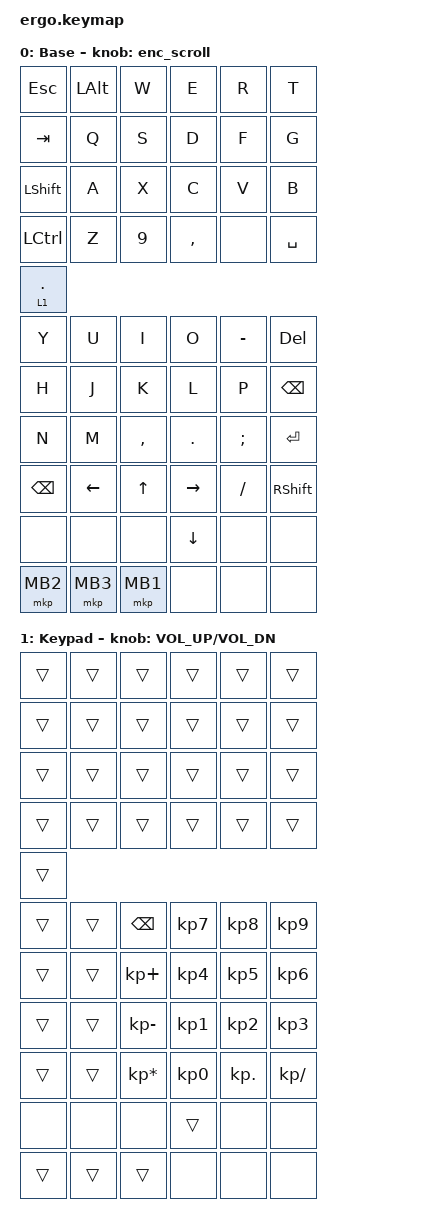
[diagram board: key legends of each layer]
#include <behaviors.dtsi>
#include <dt-bindings/zmk/keys.h>
#include <dt-bindings/zmk/bt.h>
/* Raise scroll velocity BEFORE including pointing.h. The default (10) is often
   too low for an encoder to register a wheel tick per detent - a known reason
   encoder &msc scroll appears dead. Must be defined before the header. */
#define ZMK_POINTING_DEFAULT_SCRL_VAL 80
#include <dt-bindings/zmk/pointing.h> /* &mkp for the trackpad buttons; &msc scroll */

/ {
    behaviors {
        /*
         * Positional home row mods. Studio can't tune behavior timing yet,
         * so these live here in the keymap. Usage in bindings (or in Studio):
         *     &hml LGUI A   -> hold = Left GUI, tap = A
         *     &hmr RGUI L   -> hold = Right GUI, tap = L
         *
         * "balanced" + require-prior-idle-ms keeps fast typing as taps;
         * hold-trigger-key-positions only lets a mod engage when a key on the
         * OPPOSITE hand is pressed, which kills the usual same-hand misfires.
         *   left  hand  = positions 0..24   right hand = positions 25..60
         * Tune the three *-ms values to taste once you've typed on it.
         */
        hml: home_row_mod_left {
            compatible = "zmk,behavior-hold-tap";
            #binding-cells = <2>;
            flavor = "balanced";
            tapping-term-ms = <280>;
            quick-tap-ms = <175>;
            require-prior-idle-ms = <150>;
            hold-trigger-on-release;
            bindings = <&kp>, <&kp>;
            /* opposite (right) hand */
            hold-trigger-key-positions = <25 26 27 28 29 30 31 32 33 34 35 36 37 38 39 40 41 42 43 44 45 46 47 48 49 50 51 52 53 54 55 56 57 58 59 60>;
        };
        hmr: home_row_mod_right {
            compatible = "zmk,behavior-hold-tap";
            #binding-cells = <2>;
            flavor = "balanced";
            tapping-term-ms = <280>;
            quick-tap-ms = <175>;
            require-prior-idle-ms = <150>;
            hold-trigger-on-release;
            bindings = <&kp>, <&kp>;
            /* opposite (left) hand */
            hold-trigger-key-positions = <0 1 2 3 4 5 6 7 8 9 10 11 12 13 14 15 16 17 18 19 20 21 22 23 24>;
        };

        /*
         * Encoder -> mouse scroll wheel (used by the Base layer below).
         * Wraps &msc so a turn emits scroll. Requires CONFIG_ZMK_POINTING=y.
         */
        enc_scroll: enc_scroll {
            compatible = "zmk,behavior-sensor-rotate";
            #sensor-binding-cells = <0>;
            bindings = <&msc SCRL_UP>, <&msc SCRL_DOWN>;
            tap-ms = <30>;
        };
    };

    combos {
        compatible = "zmk,combos";

        /*
         * Your board has no spare keys (all 53 switches are assigned), so
         * these actions are chords instead of dedicated keys. A combo fires
         * when its key-positions are pressed together within timeout-ms.
         * Combos are defined here in the keymap (Studio can't edit them yet).
         */

        /* ESC + Del (top outer corners) -> unlock ZMK Studio.
           Position-based, so it works regardless of the keycodes there. */
        combo_studio_unlock {
            timeout-ms = <75>;
            key-positions = <0 30>;
            bindings = <&studio_unlock>;
        };
    };

    keymap {
        compatible = "zmk,keymap";

        default_layer {
            display-name = "Base";
            /*
             * Bindings follow the combined transform in ergo.dtsi:
             * first the 25 LEFT positions, then the 36 RIGHT positions.
             */
            bindings = <
                /* ============ LEFT (positions 0..24) ============ */
                &kp ESC   &kp LALT  &kp W     &kp E     &kp R     &kp T
                &kp TAB   &kp Q     &kp S     &kp D     &kp F     &kp G
                &kp LSHFT &kp A     &kp X     &kp C     &kp V     &kp B
                &kp LCTRL &kp Z     &kp N9    &kp COMMA &none     &kp SPACE
                /* Left thumb: TAP = period, HOLD = keypad layer (layer 1).
                   This is your momentary key - hold it to type numbers. */
                &lt 1 DOT

                /* ============ RIGHT (positions 25..60) ============ */
                /* Row 0 */
                &kp Y     &kp U     &kp I     &kp O     &kp MINUS &kp DEL
                /* Row 1 */
                &kp H     &kp J     &kp K     &kp L     &kp P     &kp BSPC
                /* Row 2 */
                &kp N     &kp M     &kp COMMA &kp DOT   &kp SEMI  &kp RET
                /* Row 3 */
                &kp BSPC  &kp LEFT  &kp UP    &kp RIGHT &kp FSLH  &kp RSHFT
                /* Row 4 (positions 49-54): only DOWN (pos 52) is a real key.
                   49,50,51,53,54 are unpopulated matrix slots - no physical
                   switch exists there - so they MUST stay &none. */
                &none     &none     &none     &kp DOWN  &none     &none
                /* Row 5: the 3 keys under the trackpad = mouse buttons.
                   (Restored to plain clicks while we isolate the auto-mouse-
                   layer issue. MB1=left, MB2=right, MB3=middle.) */
                &mkp MB2  &mkp MB3  &mkp MB1  &none     &none     &none
            >;

            /* Encoder = SCROLL on base. Now uses the boosted scroll value above.
               If wheel scroll STILL doesn't register (XIAO mouse-HID can be
               flaky), swap this one line for reliable page-scroll:
                 sensor-bindings = <&inc_dec_kp PG_UP PG_DN>;
               which uses the same proven keycode path as the volume binding. */
            sensor-bindings = <&enc_scroll>;
        };

        /*
         * Keypad layer (index 1). Held via the left-thumb &lt 1 key.
         *
         * RIGHT half = numpad, transcribed from your screenshot (image 2):
         * the numbers, +, -, / and backspace read clearly. The key marked
         * (?) below I could NOT read with confidence - it's my best guess;
         * open this layer in Studio next to your saved one and fix it if
         * wrong. LEFT half is left &trans (your letters/Esc/etc. still work
         * while you hold), since image 2's left side was too blurry to trust.
         * Adjust any of this freely in Studio - it's all keymap, fully editable.
         */
        keypad_layer {
            display-name = "Keypad";
            bindings = <
                /* ============ LEFT (positions 0..24) = transparent ======== */
                &trans    &trans    &trans    &trans    &trans    &trans
                &trans    &trans    &trans    &trans    &trans    &trans
                &trans    &trans    &trans    &trans    &trans    &trans
                &trans    &trans    &trans    &trans    &trans    &trans
                &trans

                /* ============ RIGHT (positions 25..60) = numpad =========== */
                /* Row 0 */
                &trans    &trans    &kp BSPC      &kp KP_N7  &kp KP_N8  &kp KP_N9
                /* Row 1 */
                &trans    &trans    &kp KP_PLUS   &kp KP_N4  &kp KP_N5  &kp KP_N6
                /* Row 2 */
                &trans    &trans    &kp KP_MINUS  &kp KP_N1  &kp KP_N2  &kp KP_N3
                /* Row 3  (KP_MULTIPLY at pos 45 is the (?) best-guess key) */
                &trans    &trans    &kp KP_MULTIPLY &kp KP_N0 &kp KP_DOT &kp KP_DIVIDE
                /* Row 4: dead matrix slots stay &none; 52 falls through. */
                &none     &none     &none     &trans    &none     &none
                /* Row 5: trackpad buttons fall through (still click). */
                &trans    &trans    &trans    &none     &none     &none
            >;

            /* Encoder = VOLUME while the keypad layer is held (your preference). */
            sensor-bindings = <&inc_dec_kp C_VOL_UP C_VOL_DN>;
        };

        /*
         * One spare layer kept in reserve. It's invisible on a normal boot
         * (you still have just your 2 layers), but it lets you ADD a layer
         * from ZMK Studio later without reflashing. Delete this line if you
         * truly want none.
         */
        spare { status = "reserved"; };
    };
};
